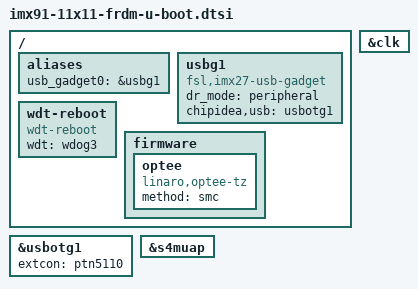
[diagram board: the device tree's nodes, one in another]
// SPDX-License-Identifier: GPL-2.0+
/*
 * Copyright 2025 NXP
 */

#include "imx91-u-boot.dtsi"

/ {
	aliases {
		usb_gadget0 = &usbg1;
	};

	usbg1: usbg1 {
		compatible = "fsl,imx27-usb-gadget";
		dr_mode = "peripheral";
		chipidea,usb = <&usbotg1>;
		status = "okay";
	};

	wdt-reboot {
		compatible = "wdt-reboot";
		wdt = <&wdog3>;
		bootph-pre-ram;
		bootph-some-ram;
	};

	firmware {
		optee {
			compatible = "linaro,optee-tz";
			method = "smc";
		};
	};
};

&usbotg1 {
	extcon = <&ptn5110>;
};

&s4muap {
	bootph-pre-ram;
	bootph-some-ram;
	status = "okay";
};

&clk {
	/delete-property/ assigned-clocks;
	/delete-property/ assigned-clock-rates;
	/delete-property/ assigned-clock-parents;
};
